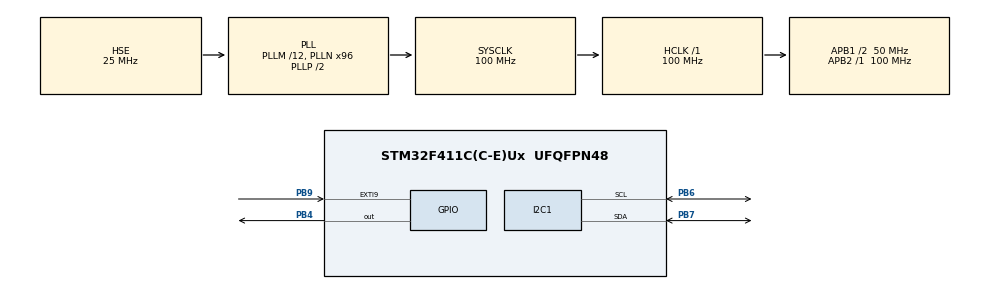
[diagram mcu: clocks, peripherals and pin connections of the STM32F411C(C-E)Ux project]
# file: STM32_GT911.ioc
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Dma.I2C1_RX.0.Direction=DMA_PERIPH_TO_MEMORY
Dma.I2C1_RX.0.FIFOMode=DMA_FIFOMODE_DISABLE
Dma.I2C1_RX.0.Instance=DMA1_Stream0
Dma.I2C1_RX.0.MemDataAlignment=DMA_MDATAALIGN_BYTE
Dma.I2C1_RX.0.MemInc=DMA_MINC_ENABLE
Dma.I2C1_RX.0.Mode=DMA_NORMAL
Dma.I2C1_RX.0.PeriphDataAlignment=DMA_PDATAALIGN_BYTE
Dma.I2C1_RX.0.PeriphInc=DMA_PINC_DISABLE
Dma.I2C1_RX.0.Priority=DMA_PRIORITY_LOW
Dma.I2C1_TX.1.Direction=DMA_MEMORY_TO_PERIPH
Dma.I2C1_TX.1.FIFOMode=DMA_FIFOMODE_DISABLE
Dma.I2C1_TX.1.Instance=DMA1_Stream6
Dma.I2C1_TX.1.MemDataAlignment=DMA_MDATAALIGN_BYTE
Dma.I2C1_TX.1.MemInc=DMA_MINC_ENABLE
Dma.I2C1_TX.1.Mode=DMA_NORMAL
Dma.I2C1_TX.1.PeriphDataAlignment=DMA_PDATAALIGN_BYTE
Dma.I2C1_TX.1.PeriphInc=DMA_PINC_DISABLE
Dma.I2C1_TX.1.Priority=DMA_PRIORITY_LOW
Dma.Request0=I2C1_RX
Dma.Request1=I2C1_TX
Mcu.Family=STM32F4
Mcu.Name=STM32F411C(C-E)Ux
Mcu.Package=UFQFPN48
NVIC.DMA1_Stream0_IRQn=true\:0\:0\:false\:false\:true\:false\:true\:true
NVIC.DMA1_Stream6_IRQn=true\:0\:0\:false\:false\:true\:false\:true\:true
NVIC.EXTI9_5_IRQn=true\:0\:0\:false\:false\:true\:true\:true\:true
NVIC.I2C1_EV_IRQn=true\:0\:0\:false\:false\:true\:true\:true\:true
NVIC.PriorityGroup=NVIC_PRIORITYGROUP_4
PA13.Mode=Serial_Wire
PA13.Signal=SYS_JTMS-SWDIO
PA14.Mode=Serial_Wire
PA14.Signal=SYS_JTCK-SWCLK
PB4.Signal=GPIO_Output
PB6.Mode=I2C
PB6.Signal=I2C1_SCL
PB7.Mode=I2C
PB7.Signal=I2C1_SDA
PB9.Signal=GPXTI9
PC14-OSC32_IN.Mode=LSE-External-Oscillator
PC14-OSC32_IN.Signal=RCC_OSC32_IN
PC15-OSC32_OUT.Mode=LSE-External-Oscillator
PC15-OSC32_OUT.Signal=RCC_OSC32_OUT
PH0\ -\ OSC_IN.Mode=HSE-External-Oscillator
PH0\ -\ OSC_IN.Signal=RCC_OSC_IN
PH1\ -\ OSC_OUT.Mode=HSE-External-Oscillator
PH1\ -\ OSC_OUT.Signal=RCC_OSC_OUT
ProjectManager.HeapSize=0x200
ProjectManager.StackSize=0x400
ProjectManager.TargetToolchain=STM32CubeIDE
RCC.48MHZClocksFreq_Value=50000000
RCC.AHBFreq_Value=100000000
RCC.APB1CLKDivider=RCC_HCLK_DIV2
RCC.APB1Freq_Value=50000000
RCC.APB1TimFreq_Value=100000000
RCC.APB2Freq_Value=100000000
RCC.APB2TimFreq_Value=100000000
RCC.CortexFreq_Value=100000000
RCC.HCLKFreq_Value=100000000
RCC.HSE_VALUE=25000000
RCC.HSI_VALUE=16000000
RCC.PLLM=12
RCC.PLLN=96
RCC.PLLSourceVirtual=RCC_PLLSOURCE_HSE
RCC.SYSCLKFreq_VALUE=100000000
RCC.SYSCLKSource=RCC_SYSCLKSOURCE_PLLCLK
RCC.VCOOutputFreq_Value=200000000
board=custom

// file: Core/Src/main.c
/* USER CODE BEGIN Header */
/**
  ******************************************************************************
  * @file           : main.c
  * @brief          : Main program body
  ******************************************************************************
  * @attention
  *
  * Copyright (c) 2023 STMicroelectronics.
  * All rights reserved.
  *
  * This software is licensed under terms that can be found in the LICENSE file
  * in the root directory of this software component.
  * If no LICENSE file comes with this software, it is provided AS-IS.
  *
  ******************************************************************************
  */
/* USER CODE END Header */
#include "main.h"

/* USER CODE BEGIN Includes */
#include "../../GT911/Inc/GT911.h"
/* USER CODE END Includes */

I2C_HandleTypeDef hi2c1;
DMA_HandleTypeDef hdma_i2c1_rx;
DMA_HandleTypeDef hdma_i2c1_tx;

void SystemClock_Config(void);
static void MX_GPIO_Init(void);
static void MX_DMA_Init(void);
static void MX_I2C1_Init(void);

int main(void)
{

  /* MCU Configuration--------------------------------------------------------*/

  /* Reset of all peripherals, Initializes the Flash interface and the Systick. */
  HAL_Init();

  /* Configure the system clock */
  SystemClock_Config();

  /* Initialize all configured peripherals */
  MX_GPIO_Init();
  MX_DMA_Init();
  MX_I2C1_Init();
  /* USER CODE BEGIN 2 */

  GT911_init();

  /* USER CODE END 2 */

  /* Infinite loop */
  while (1)
  {

  }
}

void SystemClock_Config(void)
{
  RCC_OscInitTypeDef RCC_OscInitStruct = {0};
  RCC_ClkInitTypeDef RCC_ClkInitStruct = {0};

  /** Configure the main internal regulator output voltage
  */
  __HAL_RCC_PWR_CLK_ENABLE();
  __HAL_PWR_VOLTAGESCALING_CONFIG(PWR_REGULATOR_VOLTAGE_SCALE1);

  /** Initializes the RCC Oscillators according to the specified parameters
  * in the RCC_OscInitTypeDef structure.
  */
  RCC_OscInitStruct.OscillatorType = RCC_OSCILLATORTYPE_HSE;
  RCC_OscInitStruct.HSEState = RCC_HSE_ON;
  RCC_OscInitStruct.PLL.PLLState = RCC_PLL_ON;
  RCC_OscInitStruct.PLL.PLLSource = RCC_PLLSOURCE_HSE;
  RCC_OscInitStruct.PLL.PLLM = 12;
  RCC_OscInitStruct.PLL.PLLN = 96;
  RCC_OscInitStruct.PLL.PLLP = RCC_PLLP_DIV2;
  RCC_OscInitStruct.PLL.PLLQ = 4;
  if (HAL_RCC_OscConfig(&RCC_OscInitStruct) != HAL_OK)
  {
    Error_Handler();
  }

  /** Initializes the CPU, AHB and APB buses clocks
  */
  RCC_ClkInitStruct.ClockType = RCC_CLOCKTYPE_HCLK|RCC_CLOCKTYPE_SYSCLK
                              |RCC_CLOCKTYPE_PCLK1|RCC_CLOCKTYPE_PCLK2;
  RCC_ClkInitStruct.SYSCLKSource = RCC_SYSCLKSOURCE_PLLCLK;
  RCC_ClkInitStruct.AHBCLKDivider = RCC_SYSCLK_DIV1;
  RCC_ClkInitStruct.APB1CLKDivider = RCC_HCLK_DIV2;
  RCC_ClkInitStruct.APB2CLKDivider = RCC_HCLK_DIV1;

  if (HAL_RCC_ClockConfig(&RCC_ClkInitStruct, FLASH_LATENCY_3) != HAL_OK)
  {
    Error_Handler();
  }
}

static void MX_I2C1_Init(void)
{

  hi2c1.Instance = I2C1;
  hi2c1.Init.ClockSpeed = 100000;
  hi2c1.Init.DutyCycle = I2C_DUTYCYCLE_2;
  hi2c1.Init.OwnAddress1 = 0;
  hi2c1.Init.AddressingMode = I2C_ADDRESSINGMODE_7BIT;
  hi2c1.Init.DualAddressMode = I2C_DUALADDRESS_DISABLE;
  hi2c1.Init.OwnAddress2 = 0;
  hi2c1.Init.GeneralCallMode = I2C_GENERALCALL_DISABLE;
  hi2c1.Init.NoStretchMode = I2C_NOSTRETCH_DISABLE;
  if (HAL_I2C_Init(&hi2c1) != HAL_OK)
  {
    Error_Handler();
  }

}

static void MX_DMA_Init(void)
{

  /* DMA controller clock enable */
  __HAL_RCC_DMA1_CLK_ENABLE();

  /* DMA interrupt init */
  /* DMA1_Stream0_IRQn interrupt configuration */
  HAL_NVIC_SetPriority(DMA1_Stream0_IRQn, 0, 0);
  HAL_NVIC_EnableIRQ(DMA1_Stream0_IRQn);
  /* DMA1_Stream6_IRQn interrupt configuration */
  HAL_NVIC_SetPriority(DMA1_Stream6_IRQn, 0, 0);
  HAL_NVIC_EnableIRQ(DMA1_Stream6_IRQn);

}

static void MX_GPIO_Init(void)
{
  GPIO_InitTypeDef GPIO_InitStruct = {0};

  /* GPIO Ports Clock Enable */
  __HAL_RCC_GPIOC_CLK_ENABLE();
  __HAL_RCC_GPIOH_CLK_ENABLE();
  __HAL_RCC_GPIOA_CLK_ENABLE();
  __HAL_RCC_GPIOB_CLK_ENABLE();

  /*Configure GPIO pin Output Level */
  HAL_GPIO_WritePin(GPIOB, GPIO_PIN_4, GPIO_PIN_RESET);

  /*Configure GPIO pin : PB4 */
  GPIO_InitStruct.Pin = GPIO_PIN_4;
  GPIO_InitStruct.Mode = GPIO_MODE_OUTPUT_PP;
  GPIO_InitStruct.Pull = GPIO_NOPULL;
  GPIO_InitStruct.Speed = GPIO_SPEED_FREQ_LOW;
  HAL_GPIO_Init(GPIOB, &GPIO_InitStruct);

  /*Configure GPIO pin : PB9 */
  GPIO_InitStruct.Pin = GPIO_PIN_9;
  GPIO_InitStruct.Mode = GPIO_MODE_IT_RISING;
  GPIO_InitStruct.Pull = GPIO_NOPULL;
  HAL_GPIO_Init(GPIOB, &GPIO_InitStruct);

  /* EXTI interrupt init*/
  HAL_NVIC_SetPriority(EXTI9_5_IRQn, 0, 0);
  HAL_NVIC_EnableIRQ(EXTI9_5_IRQn);

}

void Error_Handler(void)
{
  __disable_irq();
  while (1)
  {
  }
}
